VERSION ""

NS_ :

BS_:

BU_:

BO_ 2164260863 Charger_RX_BMS_TX: 8 Vector__XXX
	SG_ CV_Setpoint : 0|24@1+ (0.0001,0) [200|600] "V" Vector__XXX
	SG_ CC_Setpoint : 24|24@1+ (0.000001,0) [0|7.5] "A" Vector__XXX

BO_ 2149580799 CHARGER_RX_FAULT: 8 Vector__XXX
	SG_ BMS_Status : 0|24@1+ (1,0) [0|16777215] "" Vector__XXX

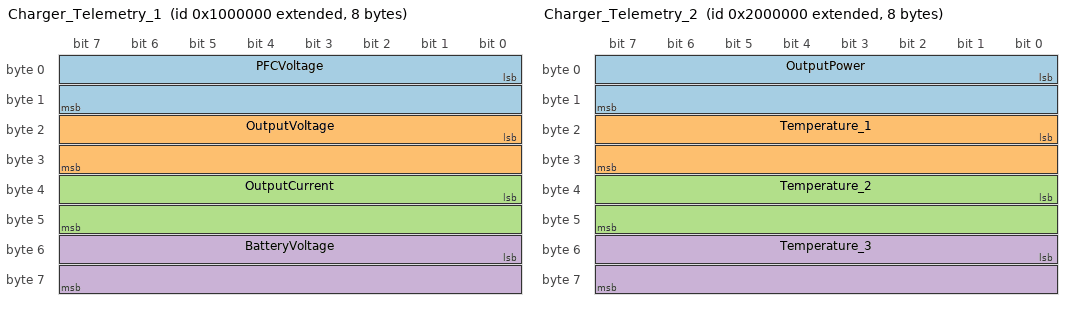
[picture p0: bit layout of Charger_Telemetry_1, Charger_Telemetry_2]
BO_ 2164260864 Charger_Telemetry_1: 8 Vector__XXX
	SG_ PFCVoltage : 0|16@1+ (0.1,0) [0|0] "V" Vector__XXX
	SG_ OutputVoltage : 16|16@1+ (0.1,0) [0|0] "V" Vector__XXX
	SG_ OutputCurrent : 32|16@1+ (0.1,0) [0|0] "A" Vector__XXX
	SG_ BatteryVoltage : 48|16@1+ (0.1,0) [0|0] "V" Vector__XXX

BO_ 2181038080 Charger_Telemetry_2: 8 Vector__XXX
	SG_ OutputPower : 0|16@1+ (1,0) [0|0] "W" Vector__XXX
	SG_ Temperature_1 : 16|16@1+ (0.1,0) [0|0] "degC" Vector__XXX
	SG_ Temperature_2 : 32|16@1+ (0.1,0) [0|0] "degC" Vector__XXX
	SG_ Temperature_3 : 48|16@1+ (0.1,0) [0|0] "degC" Vector__XXX

BO_ 2165309440 Charger_Status: 8 Vector__XXX
	SG_ STATE : 0|8@1+ (1,0) [0|0] "" Vector__XXX
	SG_ ERR_CODE : 8|16@1+ (1,0) [0|0] "" Vector__XXX

BO_ 2147483649 Charger_Discharge: 8 Vector__XXX
	SG_ RESERVED : 0|8@1+ (0,0) [0|0] "" Vector__XXX

CM_ BO_ 2164260863 "Charger RX for CCCV setpoints from BMS";
CM_ SG_ 2164260863 CV_Setpoint "Constant voltage setpoint";
CM_ SG_ 2164260863 CC_Setpoint "Constant current setpoint";

CM_ BO_ 2149580799 "BMS/AMS/IMD/SDC fault status";
CM_ SG_ 2149580799 BMS_Status "BMS fault status, 24-bit";

CM_ BO_ 2164260864 "PFC_V, V_OUT, I_OUT, V_BATT";
CM_ BO_ 2181038080 "P_OUT, TEMP_1, TEMP_2, TEMP_3";
CM_ BO_ 2165309440 "STATE, ERR_CODE";

BA_DEF_ SG_  "SPN" INT 0 524287;
BA_DEF_ BO_  "VFrameFormat" ENUM  "StandardCAN","ExtendedCAN","reserved","J1939PG";
BA_DEF_  "DatabaseVersion" STRING ;
BA_DEF_  "BusType" STRING ;
BA_DEF_  "ProtocolType" STRING ;
BA_DEF_  "DatabaseCompiler" STRING ;
BA_DEF_DEF_  "SPN" 0;
BA_DEF_DEF_  "VFrameFormat" "J1939PG";
BA_DEF_DEF_  "DatabaseVersion" "DEMO PLUS";
BA_DEF_DEF_  "BusType" "";
BA_DEF_DEF_  "ProtocolType" "";
BA_DEF_DEF_  "DatabaseCompiler" "";
BA_ "BusType" "CAN";
BA_ "DatabaseCompiler" "CSS ELECTRONICS (WWW.CSSELECTRONICS.COM)";
BA_ "DatabaseVersion" "1.0.0";
BA_ "SPN" SG_ 2164260863 CV_Setpoint 190;
SIG_VALTYPE_ 2197815296 P_OUT : 1;
SIG_VALTYPE_ 2214592512 TEMP_2 : 1;
SIG_VALTYPE_ 2197815296 TEMP_1 : 1;
SIG_VALTYPE_ 2214592512 TEMP_3 : 1;
